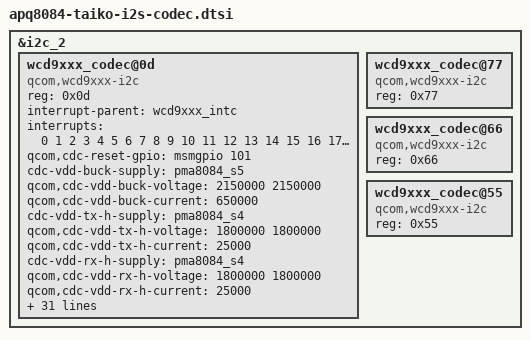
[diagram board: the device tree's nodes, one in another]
/* Copyright (c) 2014, The Linux Foundation. All rights reserved.
 *
 * This program is free software; you can redistribute it and/or modify
 * it under the terms of the GNU General Public License version 2 and
 * only version 2 as published by the Free Software Foundation.
 *
 * This program is distributed in the hope that it will be useful,
 * but WITHOUT ANY WARRANTY; without even the implied warranty of
 * MERCHANTABILITY or FITNESS FOR A PARTICULAR PURPOSE.  See the
 * GNU General Public License for more details.
 */

&i2c_2 {
	wcd9xxx_codec@0d{
		compatible = "qcom,wcd9xxx-i2c";
		reg = <0x0d>;
		interrupt-parent = <&wcd9xxx_intc>;
		interrupts = <0 1 2 3 4 5 6 7 8 9 10 11 12 13 14 15 16
			      17 18 19 20 21 22 23 24 25 26 27 28>;
		qcom,cdc-reset-gpio = <&msmgpio 101 0>;

		cdc-vdd-buck-supply = <&pma8084_s5>;
		qcom,cdc-vdd-buck-voltage = <2150000 2150000>;
		qcom,cdc-vdd-buck-current = <650000>;

		cdc-vdd-tx-h-supply = <&pma8084_s4>;
		qcom,cdc-vdd-tx-h-voltage = <1800000 1800000>;
		qcom,cdc-vdd-tx-h-current = <25000>;

		cdc-vdd-rx-h-supply = <&pma8084_s4>;
		qcom,cdc-vdd-rx-h-voltage = <1800000 1800000>;
		qcom,cdc-vdd-rx-h-current = <25000>;

		cdc-vddpx-1-supply = <&pma8084_s4>;
		qcom,cdc-vddpx-1-voltage = <1800000 1800000>;
		qcom,cdc-vddpx-1-current = <10000>;

		cdc-vdd-a-1p2v-supply = <&pma8084_l1>;
		qcom,cdc-vdd-a-1p2v-voltage = <1225000 1225000>;
		qcom,cdc-vdd-a-1p2v-current = <10000>;

		cdc-vddcx-1-supply = <&pma8084_l1>;
		qcom,cdc-vddcx-1-voltage = <1225000 1225000>;
		qcom,cdc-vddcx-1-current = <10000>;

		cdc-vddcx-2-supply = <&pma8084_l1>;
		qcom,cdc-vddcx-2-voltage = <1225000 1225000>;
		qcom,cdc-vddcx-2-current = <10000>;

		qcom,cdc-static-supplies = "cdc-vdd-buck",
					   "cdc-vdd-tx-h",
					   "cdc-vdd-rx-h",
					   "cdc-vddpx-1",
					   "cdc-vdd-a-1p2v",
					   "cdc-vddcx-1",
					   "cdc-vddcx-2";

		qcom,cdc-micbias-ldoh-v = <0x3>;
		qcom,cdc-micbias-cfilt1-mv = <1800>;
		qcom,cdc-micbias-cfilt2-mv = <2700>;
		qcom,cdc-micbias-cfilt3-mv = <1800>;
		qcom,cdc-micbias1-cfilt-sel = <0x0>;
		qcom,cdc-micbias2-cfilt-sel = <0x1>;
		qcom,cdc-micbias3-cfilt-sel = <0x2>;
		qcom,cdc-micbias4-cfilt-sel = <0x2>;
		qcom,cdc-mclk-clk-rate = <12288000>;
		qcom,cdc-micbias1-ext-cap;
		qcom,cdc-micbias2-ext-cap;
		qcom,cdc-micbias3-ext-cap;

		/*
		 * spkrdrv supply in MTP device is from VPH_PWR which is
		 * always ON. Give a dummy supply to make codec driver happy.
		 */
		cdc-vdd-spkdrv-supply = <&vph_pwr_vreg>;
		qcom,cdc-vdd-spkdrv-voltage = <0 0>;
		qcom,cdc-vdd-spkdrv-current = <0>;
		qcom,cdc-on-demand-supplies = "cdc-vdd-spkdrv";
	};

	wcd9xxx_codec@77{
		compatible = "qcom,wcd9xxx-i2c";
		reg = <0x77>;
	};

	wcd9xxx_codec@66{
		compatible = "qcom,wcd9xxx-i2c";
		reg = <0x66>;
	};

	wcd9xxx_codec@55{
		compatible = "qcom,wcd9xxx-i2c";
		reg = <0x55>;
	};
};
